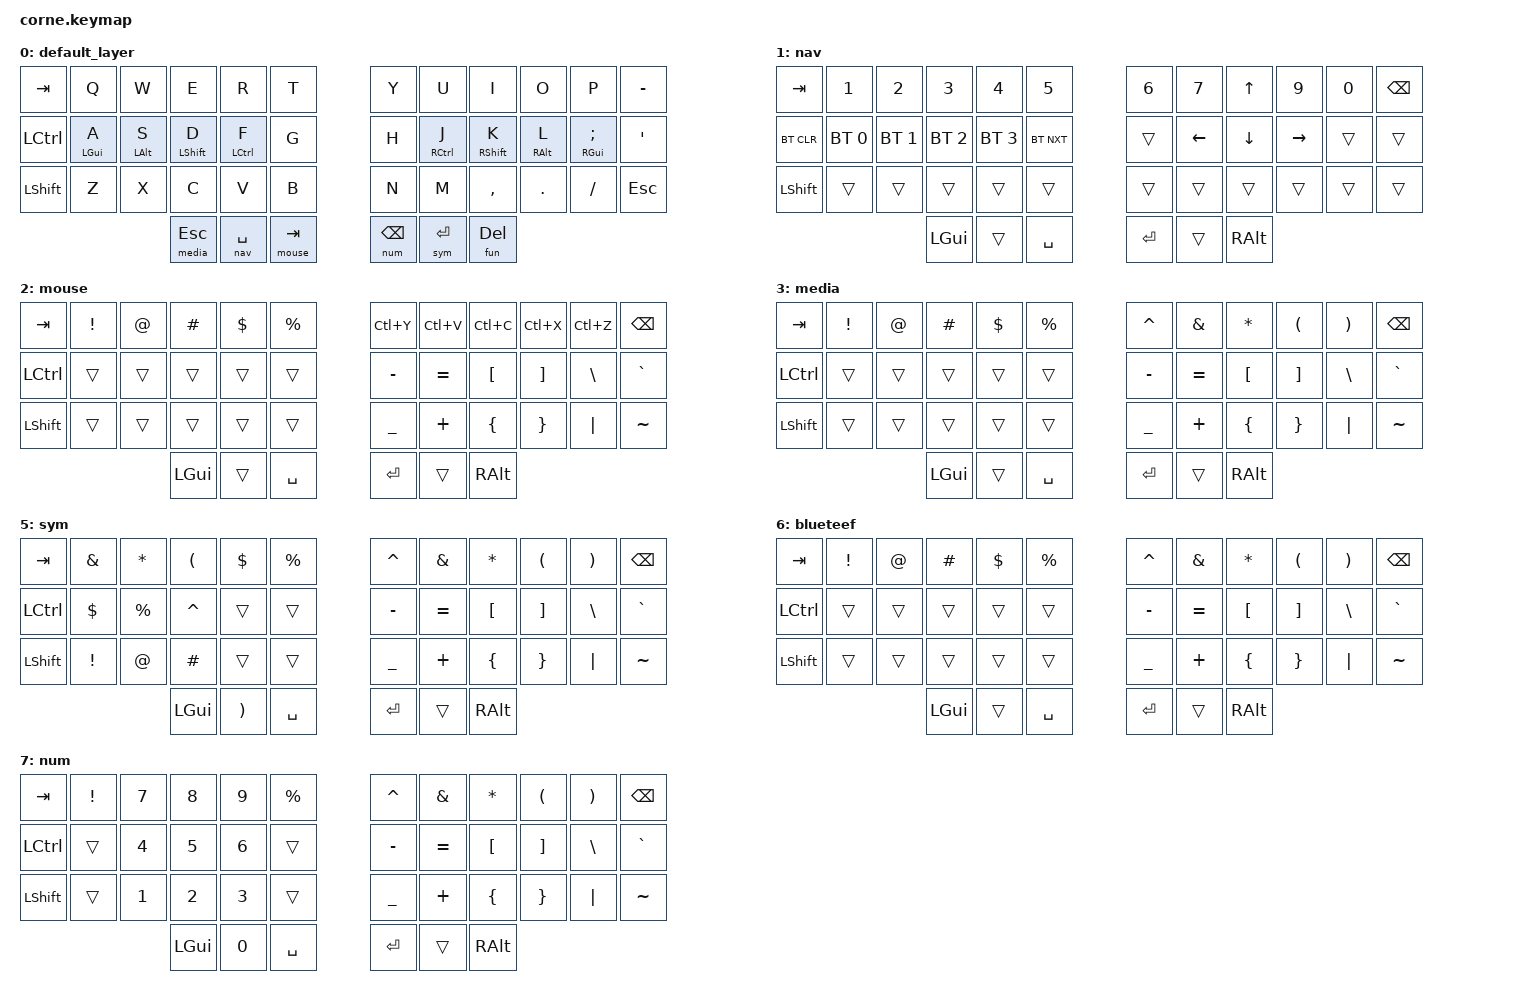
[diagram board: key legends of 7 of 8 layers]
/*
 * Copyright (c) 2020 The ZMK Contributors
 *
 * SPDX-License-Identifier: MIT
 */

#include <behaviors.dtsi>
#include <dt-bindings/zmk/bt.h>
#include <dt-bindings/zmk/keys.h>

#define default_layer 0
#define nav   1
#define mouse   2
#define media   3
#define fun 4
#define sym 5
#define blueteef 6
#define num 7

/ {
    combos {
        compatible = "zmk,combos";

        semcol {
            bindings = <&kp SEMI>;
            key-positions = <32 33>;
            timeout-ms = <50>;
            layers = <0>;
        };

        cpslck {
            bindings = <&kp CAPSLOCK>;
            key-positions = <24 35>;
            layers = <0>;
        };

        parentheses_left {
            bindings = <&kp LEFT_PARENTHESIS>;
            key-positions = <16 15>;
            layers = <0>;
        };

        parentheses_right {
            bindings = <&kp RIGHT_PARENTHESIS>;
            key-positions = <19 20>;
            layers = <0>;
        };

        bracket_left {
            bindings = <&kp LEFT_BRACKET>;
            key-positions = <3 4>;
            layers = <0>;
        };

        bracket_right {
            bindings = <&kp RIGHT_BRACKET>;
            key-positions = <8 7>;
            layers = <0>;
        };

        colon {
            bindings = <&kp COLON>;
            key-positions = <20 21>;
            layers = <0>;
        };

        grave {
            bindings = <&kp GRAVE>;
            key-positions = <15 14>;
            layers = <0>;
        };

        brace_left {
            bindings = <&kp LEFT_BRACE>;
            key-positions = <27 28>;
            layers = <0>;
        };

        brace_right {
            bindings = <&kp RIGHT_BRACE>;
            key-positions = <31 32>;
            layers = <0>;
        };

        less_than {
            bindings = <&kp LESS_THAN>;
            key-positions = <2 3>;
            layers = <0>;
        };

        bigger_than {
            bindings = <&kp GREATER_THAN>;
            key-positions = <8 9>;
            layers = <0>;
        };
    };

    behaviors {
        hml: hml {
            compatible = "zmk,behavior-hold-tap";
            label = "HML";
            bindings = <&kp>, <&kp>;

            #binding-cells = <2>;
            tapping-term-ms = <280>;
            quick-tap-ms = <175>;
            flavor = "balanced";
            hold-trigger-on-release;
            hold-trigger-key-positions = <6 7 8 9 10 11 18 19 20 21 22 23 30 31 32 33 34 35 38 39 40 41 37 36>;
            require-prior-idle-ms = <150>;
        };

        hmr: hmr {
            compatible = "zmk,behavior-hold-tap";
            label = "HMR";
            bindings = <&kp>, <&kp>;

            #binding-cells = <2>;
            tapping-term-ms = <280>;
            quick-tap-ms = <175>;
            hold-trigger-on-release;
            hold-trigger-key-positions = <0 1 2 3 4 5 12 13 14 15 16 17 24 25 26 27 28 29 36 37 38 39 40 41>;
            flavor = "balanced";
            require-prior-idle-ms = <150>;
        };

        lrt: lrt {
            compatible = "zmk,behavior-hold-tap";
            label = "LRT";
            bindings = <&mo>, <&kp>;

            #binding-cells = <2>;
            tapping-term-ms = <150>;
            flavor = "tap-preferred";
        };
    };

    keymap {
        compatible = "zmk,keymap";

        default_layer {
            // -----------------------------------------------------------------------------------------
            // |  TAB |  Q  |  W  |  E  |  R  |  T  |   |  Y  |  U   |  I  |  O  |  P  |  -   |
            // | CTRL |  A  |  S  |  D  |  F  |  G  |   |  H  |  J   |  K  |  L  |  ;  |  '   |
            // | SHFT |  Z  |  X  |  C  |  V  |  B  |   |  N  |  M   |  ,  |  .  |  /  | ESC  |
            //                    | media\ESC | nav SPACE | mouse\TAB |   | num\BSPC | sym\ENTER  | fun\DEL |

            bindings = <
&kp TAB    &kp Q       &kp W       &kp E          &kp R          &kp T            &kp Y         &kp U        &kp I        &kp O       &kp P          &kp MINUS
&kp LCTRL  &mt LGUI A  &mt LALT S  &mt LSHFT D    &mt LCTRL F    &kp G            &kp H         &mt RCTRL J  &mt RSHFT K  &mt RALT L  &mt RGUI SEMI  &kp SQT
&kp LSHFT  &kp Z       &kp X       &kp C          &kp V          &kp B            &kp N         &kp M        &kp COMMA    &kp DOT     &kp FSLH       &kp ESC
                                   &lt media ESC  &lt nav SPACE  &lt mouse TAB    &lt num BSPC  &lt sym RET  &lt fun DEL
            >;
        };

        nav {
            // -----------------------------------------------------------------------------------------
            // |  TAB |  1  |  2  |  3  |  4  |  5  |   |  6  |  7  | UP  |  9  |  0  | BSPC |
            // | BTCLR| BT1 | BT2 | BT3 | BT4 | BT5 |   |     | LFT | DOWN| RGT |     |      |
            // | SHFT |     |     |     |     |     |   |     |     |     |     |     |      |
            //                    | GUI |     | SPC |   | ENT |     | ALT |

            bindings = <
&kp TAB     &kp N1        &kp N2        &kp N3        &kp N4        &kp N5        &kp N6   &kp N7    &kp UP    &kp N9     &kp N0  &kp BSPC
&bt BT_CLR  &bt BT_SEL 0  &bt BT_SEL 1  &bt BT_SEL 2  &bt BT_SEL 3  &bt BT_NXT    &trans   &kp LEFT  &kp DOWN  &kp RIGHT  &trans  &trans
&kp LSHFT   &trans        &trans        &trans        &trans        &trans        &trans   &trans    &trans    &trans     &trans  &trans
                                        &kp LGUI      &trans        &kp SPACE     &kp RET  &trans    &kp RALT
            >;
        };

        mouse {
            // -----------------------------------------------------------------------------------------
            // |  TAB |  !  |  @  |  #  |  $  |  %  |   | Redo| Paste   |  Copy  |  Cut   | Undo  | BSPC |
            // | CTRL |     |     |     |     |     |   |  -  |  =      |  [     |  ]     |       |  `   |
            // | SHFT |     |     |     |     |     |   |  _  |  +      |  {     |  }     |   "|" |  ~   |
            //                    | GUI |     | SPC |   | ENT |     | ALT |

            bindings = <
&kp TAB    &kp EXCL  &kp AT  &kp HASH  &kp DLLR  &kp PRCNT    &kp LC(Y)  &kp LC(V)  &kp LC(C)  &kp LC(X) &kp LC(Z)  &kp BSPC
&kp LCTRL  &trans    &trans  &trans    &trans    &trans       &kp MINUS  &kp EQUAL  &kp LBKT   &kp RBKT  &kp BSLH  &kp GRAVE
&kp LSHFT  &trans    &trans  &trans    &trans    &trans       &kp UNDER  &kp PLUS   &kp LBRC   &kp RBRC  &kp PIPE  &kp TILDE
                             &kp LGUI  &trans    &kp SPACE    &kp RET    &trans     &kp RALT
            >;
        };

        media {
            // -----------------------------------------------------------------------------------------
            // |  TAB |  !  |  @  |  #  |  $  |  %  |   |  ^  |  &  |  *  |  (  |  )  | BSPC |
            // | CTRL |     |     |     |     |     |   |  -  |  =  |  [  |  ]  |  \  |  `   |
            // | SHFT |     |     |     |     |     |   |  _  |  +  |  {  |  }  | "|" |  ~   |
            //                    | GUI |     | SPC |   | ENT |     | ALT |

            bindings = <
&kp TAB    &kp EXCL  &kp AT  &kp HASH  &kp DLLR  &kp PRCNT    &kp CARET  &kp AMPS   &kp ASTRK  &kp LPAR  &kp RPAR  &kp BSPC
&kp LCTRL  &trans    &trans  &trans    &trans    &trans       &kp MINUS  &kp EQUAL  &kp LBKT   &kp RBKT  &kp BSLH  &kp GRAVE
&kp LSHFT  &trans    &trans  &trans    &trans    &trans       &kp UNDER  &kp PLUS   &kp LBRC   &kp RBRC  &kp PIPE  &kp TILDE
                             &kp LGUI  &trans    &kp SPACE    &kp RET    &trans     &kp RALT
            >;
        };

        fun {
            // -----------------------------------------------------------------------------------------
            // |  TAB |  !  |  @  |  #  |  $  |  %  |   |  ^  |  &  |  *  |  (  |  )  | BSPC |
            // | CTRL |     |     |     |     |     |   |  -  |  =  |  [  |  ]  |  \  |  `   |
            // | SHFT | F10 |     |     |     |     |   |  _  |  +  |  {  |  }  | "|" |  ~   |
            //                    | GUI |     | SPC |   | ENT |     | ALT |

            bindings = <
&kp TAB  &kp F12  &kp F7  &kp F8  &kp F9     &kp CARET    &kp AMPS   &kp ASTRK  &kp LPAR  &kp RPAR  &kp BSPC   &kp LCTRL
&kp F11  &kp F4   &kp F5  &kp F6  &trans     &kp MINUS    &kp EQUAL  &kp LBKT   &kp RBKT  &kp BSLH  &kp GRAVE  &kp LSHFT
&kp F10  &kp F1   &kp F2  &kp F3  &trans     &kp UNDER    &kp PLUS   &kp LBRC   &kp RBRC  &kp PIPE  &kp TILDE  &kp LGUI
                          &trans  &kp SPACE  &kp RET      &trans     &kp RALT
            >;
        };

        sym {
            // -----------------------------------------------------------------------------------------
            // |  TAB |  &  |  *  |  (  |  $  |  %  |   |  ^  |  &  |  *  |  (  |  )  | BSPC |
            // | CTRL |  $  |  %  |  ^  |     |     |   |  -  |  =  |  [  |  ]  |  \  |  `   |
            // | SHFT |  !  |  @  |  #  |     |     |   |  _  |  +  |  {  |  }  | "|" |  ~   |
            //                    | GUI |  )  | SPC |   | ENT |     | ALT |

            bindings = <
&kp TAB    &kp AMPS  &kp ASTRK  &kp LPAR   &kp DLLR  &kp PRCNT    &kp CARET  &kp AMPS   &kp ASTRK  &kp LPAR  &kp RPAR  &kp BSPC
&kp LCTRL  &kp DLLR  &kp PRCNT  &kp CARET  &trans    &trans       &kp MINUS  &kp EQUAL  &kp LBKT   &kp RBKT  &kp BSLH  &kp GRAVE
&kp LSHFT  &kp EXCL  &kp AT     &kp HASH   &trans    &trans       &kp UNDER  &kp PLUS   &kp LBRC   &kp RBRC  &kp PIPE  &kp TILDE
                                &kp LGUI   &kp RPAR  &kp SPACE    &kp RET    &trans     &kp RALT
            >;
        };

        blueteef {
            // -----------------------------------------------------------------------------------------
            // |  TAB |  1  |  2  |  3  |  4  |  5  |   |  6  |  7  | UP  |  9  |  0  | BSPC |
            // | BTCLR| BT1 | BT2 | BT3 | BT4 | BT5 |   |     | LFT | DOWN| RGT |     |      |
            // | SHFT |     |     |     |     |     |   |     |     |     |     |     |      |
            //                    | GUI |     | SPC |   | ENT |     | ALT |

            bindings = <
&kp TAB    &kp EXCL  &kp AT  &kp HASH  &kp DLLR  &kp PRCNT    &kp CARET  &kp AMPS   &kp ASTRK  &kp LPAR  &kp RPAR  &kp BSPC
&kp LCTRL  &trans    &trans  &trans    &trans    &trans       &kp MINUS  &kp EQUAL  &kp LBKT   &kp RBKT  &kp BSLH  &kp GRAVE
&kp LSHFT  &trans    &trans  &trans    &trans    &trans       &kp UNDER  &kp PLUS   &kp LBRC   &kp RBRC  &kp PIPE  &kp TILDE
                             &kp LGUI  &trans    &kp SPACE    &kp RET    &trans     &kp RALT
            >;
        };

        num {
            // -----------------------------------------------------------------------------------------
            // |  TAB |  1  |  7  |  8  |  9  |  5  |   |  6  |  7  | UP  |  9  |  0  | BSPC |
            // | BTCLR| BT1 |  4  |  5  |  6  | BT5 |   |     | LFT | DOWN| RGT |     |      |
            // | SHFT |     |  1  |  2  |  3  |     |   |     |     |     |     |     |      |
            //                    | GUI |  0  | SPC |   | ENT |     | ALT |

            bindings = <
&kp TAB    &kp EXCL  &kp N7  &kp N8    &kp N9  &kp PRCNT    &kp CARET  &kp AMPS   &kp ASTRK  &kp LPAR  &kp RPAR  &kp BSPC
&kp LCTRL  &trans    &kp N4  &kp N5    &kp N6  &trans       &kp MINUS  &kp EQUAL  &kp LBKT   &kp RBKT  &kp BSLH  &kp GRAVE
&kp LSHFT  &trans    &kp N1  &kp N2    &kp N3  &trans       &kp UNDER  &kp PLUS   &kp LBRC   &kp RBRC  &kp PIPE  &kp TILDE
                             &kp LGUI  &kp N0  &kp SPACE    &kp RET    &trans     &kp RALT
            >;
        };
    };
};
